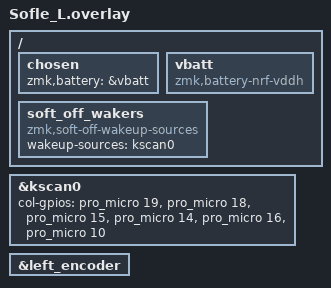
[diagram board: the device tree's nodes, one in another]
/*
 * Copyright (c) 2020 Ryan Cross
 *
 * SPDX-License-Identifier: MIT
 */

#include "Sofle.dtsi"

&kscan0 {
    col-gpios
        = <&pro_micro 19 GPIO_ACTIVE_HIGH>
        , <&pro_micro 18 GPIO_ACTIVE_HIGH>
        , <&pro_micro 15 GPIO_ACTIVE_HIGH>
        , <&pro_micro 14 GPIO_ACTIVE_HIGH>
        , <&pro_micro 16 GPIO_ACTIVE_HIGH>
        , <&pro_micro 10 GPIO_ACTIVE_HIGH>
        ;
};

&left_encoder {
    status = "okay";
};
/ {
    chosen {
      zmk,battery = &vbatt;
    };

    vbatt: vbatt {
        compatible = "zmk,battery-nrf-vddh";
    };
};

// Soft off: sem uma fonte de wakeup explicita o ZMK so sai do soft off por
// reset/power cycle. Usa a propria matriz como waker: qualquer tecla da
// metade esquerda religa o central.
/ {
    soft_off_wakers {
        compatible = "zmk,soft-off-wakeup-sources";
        wakeup-sources = <&kscan0>;
    };
};
